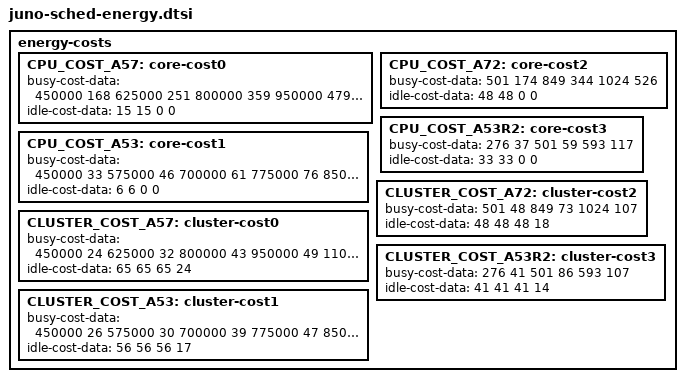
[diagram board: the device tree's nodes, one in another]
/*
 * ARM JUNO specific energy cost model data. There are no unit requirements for
 * the data. Data can be normalized to any reference point, but the
 * normalization must be consistent. That is, one bogo-joule/watt must be the
 * same quantity for all data, but we don't care what it is.
 */

energy-costs {
	/* Juno r0 Energy */
	CPU_COST_A57: core-cost0 {
		busy-cost-data = <
			450000   168
			625000   251
			800000   359
			950000   479
			1100000  616
		>;
		idle-cost-data = <
			15
			15
			 0
			 0
		>;
	};
	CPU_COST_A53: core-cost1 {
		busy-cost-data = <
			450000    33
			575000    46
			700000    61
			775000    76
			850000    93
		>;
		idle-cost-data = <
		      6
		      6
		      0
		      0
		>;
	};
	CLUSTER_COST_A57: cluster-cost0 {
		busy-cost-data = <
			450000    24
			625000    32
			800000    43
			950000    49
			1100000   64
		>;
		idle-cost-data = <
			 65
			 65
			 65
			 24
		>;
	};
	CLUSTER_COST_A53: cluster-cost1 {
		busy-cost-data = <
			450000    26
			575000    30
			700000    39
			775000    47
			850000    57
		>;
		idle-cost-data = <
			56
			56
			56
			17
		>;
	};
	/* Juno r2 Energy */
	CPU_COST_A72: core-cost2 {
		busy-cost-data = <
			501   174
			849   344
			1024   526
		>;
		idle-cost-data = <
		      48
		      48
		       0
		       0
		>;
	};
	CPU_COST_A53R2: core-cost3 {
		busy-cost-data = <
			276    37
			501    59
			593   117
		>;
		idle-cost-data = <
		      33
		      33
		      0
		      0
		>;
	};
	CLUSTER_COST_A72: cluster-cost2 {
		busy-cost-data = <
			501    48
			849    73
			1024   107
		>;
		idle-cost-data = <
			 48
			 48
			 48
			 18
		>;
	};
	CLUSTER_COST_A53R2: cluster-cost3 {
		busy-cost-data = <
			276    41
			501    86
			593   107
		>;
		idle-cost-data = <
			41
			41
			41
			14
		>;
	};
};
